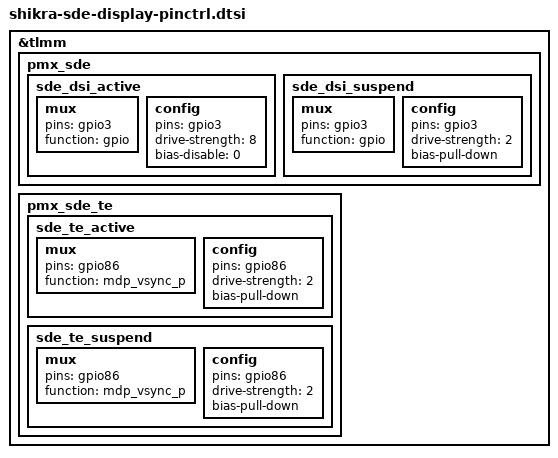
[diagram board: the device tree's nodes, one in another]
// SPDX-License-Identifier: BSD-3-Clause
/*
 * Copyright (c) Qualcomm Technologies, Inc. and/or its subsidiaries.
 */

&tlmm {
	pmx_sde: pmx_sde {
		sde_dsi_active: sde_dsi_active {
			mux {
				pins = "gpio3";
				function = "gpio";
			};

			config {
				pins = "gpio3";
				drive-strength = <8>;   /* 8 mA */
				bias-disable = <0>;   /* no pull */
			};
		};

		sde_dsi_suspend: sde_dsi_suspend {
			mux {
				pins = "gpio3";
				function = "gpio";
			};

			config {
				pins = "gpio3";
				drive-strength = <2>;   /* 2 mA */
				bias-pull-down;         /* PULL DOWN */
			};
		};
	};

	pmx_sde_te: pmx_sde_te {
		sde_te_active: sde_te_active {
			mux {
				pins = "gpio86";
				function = "mdp_vsync_p";
			};

			config {
				pins = "gpio86";
				drive-strength = <2>;   /* 2 mA */
				bias-pull-down;         /* PULL DOWN */
			};
		};

		sde_te_suspend: sde_te_suspend {
			mux {
				pins = "gpio86";
				function = "mdp_vsync_p";
			};

			config {
				pins = "gpio86";
				drive-strength = <2>;   /* 2 mA */
				bias-pull-down;         /* PULL DOWN */
			};
		};
	};
};
